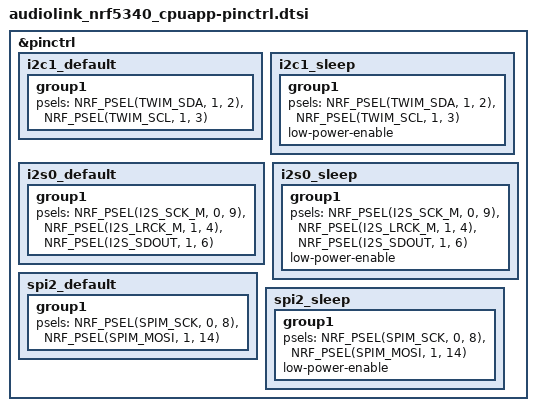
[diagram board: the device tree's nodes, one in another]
&pinctrl {
	i2c1_default: i2c1_default {
		group1 {
			psels = <NRF_PSEL(TWIM_SDA, 1, 2)>,
				<NRF_PSEL(TWIM_SCL, 1, 3)>;
		};
	};

	i2c1_sleep: i2c1_sleep {
		group1 {
			psels = <NRF_PSEL(TWIM_SDA, 1, 2)>,
				<NRF_PSEL(TWIM_SCL, 1, 3)>;
			low-power-enable;
		};
	};

	/* No MCK: R6 is not fitted, the PCM5242 derives its clocks from BCK. */
	i2s0_default: i2s0_default {
		group1 {
			psels = <NRF_PSEL(I2S_SCK_M, 0, 9)>,
				<NRF_PSEL(I2S_LRCK_M, 1, 4)>,
				<NRF_PSEL(I2S_SDOUT, 1, 6)>;
		};
	};

	i2s0_sleep: i2s0_sleep {
		group1 {
			psels = <NRF_PSEL(I2S_SCK_M, 0, 9)>,
				<NRF_PSEL(I2S_LRCK_M, 1, 4)>,
				<NRF_PSEL(I2S_SDOUT, 1, 6)>;
			low-power-enable;
		};
	};

	/*
	 * WS2812 data only. The SPIM still needs an SCK pin to complete transfers,
	 * so it gets P0.08, which is not connected on the board.
	 */
	spi2_default: spi2_default {
		group1 {
			psels = <NRF_PSEL(SPIM_SCK, 0, 8)>,
				<NRF_PSEL(SPIM_MOSI, 1, 14)>;
		};
	};

	spi2_sleep: spi2_sleep {
		group1 {
			psels = <NRF_PSEL(SPIM_SCK, 0, 8)>,
				<NRF_PSEL(SPIM_MOSI, 1, 14)>;
			low-power-enable;
		};
	};
};
